# RA4M1 register map
Vendor: Renesas Electronics Corporation; Series: RA4; File version: 1.2
CPU: CM4 r0p1, little endian, MPU, FPU, VTOR, 4 interrupt priority bits
Registers are 8-bit, read-write, reset 0x0 unless marked. A register's access mark holds for its fields unless they carry their own. Offsets are from the block's base; [hi:lo] are bit positions; {n}, {i} and the like mark numbered series.

## DAC12 — 12-bit D/A converter
Base 0x4005E000
0x00 DADR0 16-bit — D/A Data Register 0
  [15:0] DADR — D/A Data Register NOTE: When DADPR.DPSEL = 0, the high-order 4 bits are fixed to 0: right justified format. When DADPR.DPSEL = 1, the low-order 4 bits are fixed to 0: left justified format.
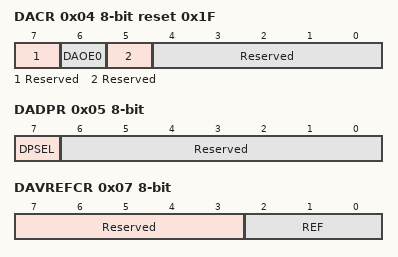
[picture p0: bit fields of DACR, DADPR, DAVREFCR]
0x04 DACR reset 0x1F — D/A Control Register
  [7] Reserved — This bit is read as 0. The write value should be 0.
  [6] DAOE0 — D/A Output Enable 0
    0=Analog output of channel 0 (DA0) is disabled; 1=D/A conversion of channel 0 is enabled. Analog output of channel 0 (DA0) is enabled.
  [5] Reserved — This bit is read as 0. The write value should be 0.
  [4:0] Reserved — These bits are read as 11111. The write value should be 11111.
0x05 DADPR — DADR0 Format Select Register
  [7] DPSEL — DADRm Format Select
    0=Right justified format; 1=Left justified format
  [6:0] Reserved — These bits are read as 0000000. The write value should be 0000000.
0x06 DAADSCR — D/A-A/D Synchronous Start Control Register
  [7] DAADST — D/A-A/D Synchronous Conversion
    0=D/A converter operation does not synchronize with A/D converter operation (unit 1) (countermeasure against interference between D/A and A/D conversions is disabled); 1=D/A converter operation synchronizes with A/D converter operation (unit 1) (countermeasure against interference between D/A and A/D conversions is enabled)
0x07 DAVREFCR — D/A VREF Control Register
  [7:3] Reserved — These bits are read as 00000. The write value should be 00000.
  [2:0] REF — D/A Reference Voltage Select
    0=Not selected; 1=AVCC0/AVSS0; 3=Internal reference voltage/AVSS0; 6=VREFH/VREFL; other=others (Setting prohibited)

## DAC8 — 8-bit D/A converter
Base 0x4009E000
{0x0+i} DACS{i} (i=0..1) — D/A Conversion Value Setting Register {i}
  [7:0] DACS — DACS D/A conversion store data note: When 8-bit D/A Converter output is selected as the reference input for the ACMPLP in the COMPSEL1 register, and ACMPLP operation is enabled (COMPMDR.CnENB = 1), changing the DACS[7:0] bits for the channel in use is prohibited.
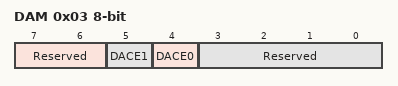
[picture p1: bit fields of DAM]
0x03 DAM — D/A Converter Mode Register
  [7:6] Reserved — These bits are read as 00. The write value should be 00.
  [5] DACE1 — D/A Operation Enable 1
    0=D/A conversion disabled for channel 1; 1=D/A conversion enabled for channel 1
  [4] DACE0 — D/A Operation Enable 0
    0=D/A conversion disabled for channel 0; 1=D/A conversion enabled for channel 0
  [3:0] Reserved — These bits are read as 0000. The write value should be 0000.

## DMA — DMAC Module Activation
Base 0x40005200
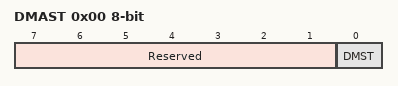
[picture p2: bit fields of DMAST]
0x00 DMAST — DMAC Module Activation Register
  [7:1] Reserved — These bits are read as 0000000. The write value should be 0000000.
  [0] DMST — DMAC Operation Enable
    0=Disabled; 1=Enabled

## DOC — Data Operation Circuit
Base 0x40054100
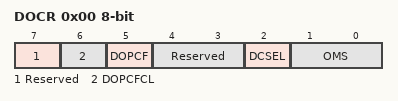
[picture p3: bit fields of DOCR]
0x00 DOCR — DOC Control Register
  [7] Reserved — This bit is read as 0. The write value should be 0.
  [6] DOPCFCL — DOPCF Clear
    0=Maintains the DOPCF flag state; 1=Clears the DOPCF flag
  [5] DOPCF ro — Data Operation Circuit Flag Indicates the result of an operation.
  [4:3] Reserved — These bits are read as 00. The write value should be 00.
  [2] DCSEL — Detection Condition Select
    0=DOPCF is set when data mismatch is detected; 1=DOPCF is set when data match is detected
  [1:0] OMS — Operating Mode Select
    0=Data comparison mode; 1=Data addition mode; 2=Data subtraction mode; 3=Setting prohibited
0x02 DODIR 16-bit — DOC Data Input Register
  [15:0] DODIR — 16-bit read-write register in which 16-bit data for use in the operations are stored.
0x04 DODSR 16-bit — DOC Data Setting Register
  [15:0] DODSR — This register stores 16-bit data for use as a reference in data comparison mode. This register also stores the results of operations in data addition and data subtraction modes.
